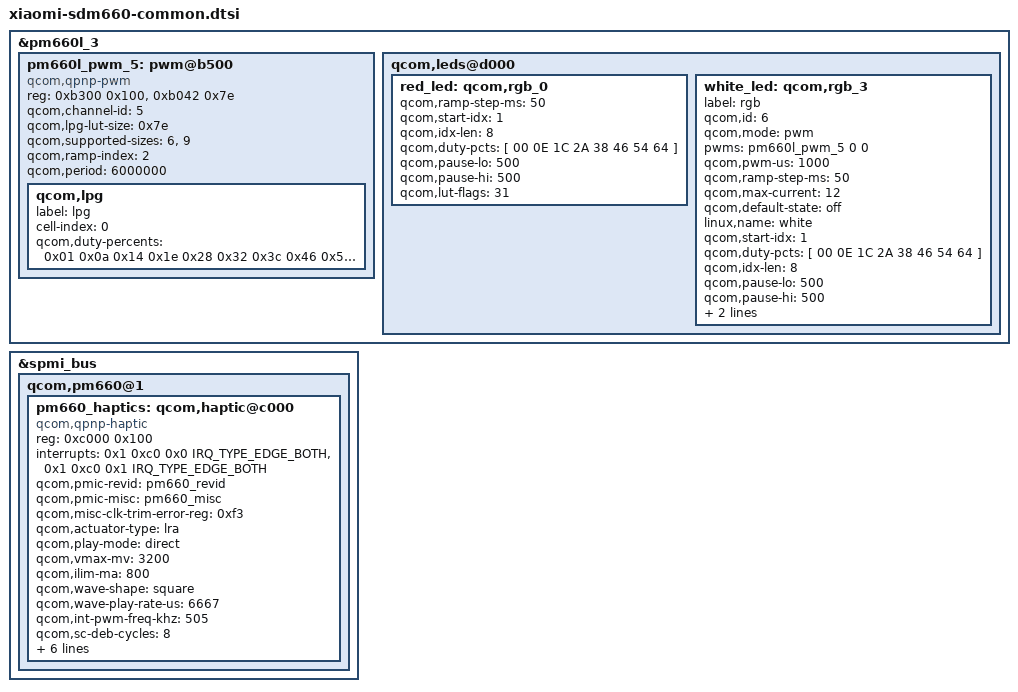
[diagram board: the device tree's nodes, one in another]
/* Red led was used for powersupply of White led */
&pm660l_3 {
	pm660l_pwm_5: pwm@b500 {
		compatible = "qcom,qpnp-pwm";
		reg = <0xb300 0x100>,
		      <0xb042 0x7e>;
		reg-names = "qpnp-lpg-channel-base",
				 "qpnp-lpg-lut-base";
		qcom,channel-id = <5>;
		qcom,lpg-lut-size = <0x7e>;
		qcom,supported-sizes = <6>, <9>;
		qcom,ramp-index = <2>;
		#pwm-cells = <2>;
		qcom,period = <6000000>;

		qcom,lpg {
			label = "lpg";
			cell-index = <0>;
			qcom,duty-percents =
				<0x01 0x0a 0x14 0x1e 0x28 0x32 0x3c
				0x46 0x50 0x5a 0x64
				0x64 0x5a 0x50 0x46 0x3c 0x32 0x28 0x1e
				0x14 0x0a 0x01>;
		};
	};

	qcom,leds@d000 {
		red_led: qcom,rgb_0 {
			qcom,ramp-step-ms = <50>;
			qcom,start-idx = <1>;
			qcom,idx-len = <8>;
			qcom,duty-pcts = [ 00 0E 1C 2A 38 46 54 64 ];
			qcom,pause-lo = <500>;
			qcom,pause-hi = <500>;
			qcom,lut-flags = <31>; /* loop, ramp up, reverse, pause hi, pause lo */
		};

		white_led: qcom,rgb_3 {
			label = "rgb";
			qcom,id = <6>;
			qcom,mode = "pwm";
			pwms = <&pm660l_pwm_5 0 0>;
			qcom,pwm-us = <1000>;
			qcom,ramp-step-ms = <50>;
			qcom,max-current = <12>;
			qcom,default-state = "off";
			linux,name = "white";
			qcom,start-idx = <1>;
			qcom,duty-pcts = [ 00 0E 1C 2A 38 46 54 64 ];
			qcom,idx-len = <8>;
			qcom,pause-lo = <500>;
			qcom,pause-hi = <500>;
			qcom,lut-flags = <31>; /* loop, ramp up, reverse, pause hi, pause lo */
			qcom,use-blink;
		};
	};
};

&spmi_bus {
	qcom,pm660@1 {
		/delete-node/ qcom,haptics@c000;
		pm660_haptics: qcom,haptic@c000 {
			compatible = "qcom,qpnp-haptic";
			reg = <0xc000 0x100>;
			interrupts = <0x1 0xc0 0x0 IRQ_TYPE_EDGE_BOTH>,
					<0x1 0xc0 0x1 IRQ_TYPE_EDGE_BOTH>;
			interrupt-names = "sc-irq", "play-irq";
			qcom,pmic-revid = <&pm660_revid>;
			qcom,pmic-misc = <&pm660_misc>;
			qcom,misc-clk-trim-error-reg = <0xf3>;
			qcom,actuator-type = "lra";
			qcom,play-mode = "direct";
			qcom,vmax-mv = <3200>;
			qcom,ilim-ma = <800>;
			qcom,wave-shape = "square";
			qcom,wave-play-rate-us = <6667>;
			qcom,int-pwm-freq-khz = <505>;
			qcom,sc-deb-cycles = <8>;
			qcom,en-brake;
			qcom,brake-pattern = [03 03 00 00];
			qcom,lra-high-z = "opt0";
			qcom,lra-auto-res-mode = "qwd";
			qcom,lra-calibrate-at-eop = <0>;
			qcom,correct-lra-drive-freq;
		};
	};
};
